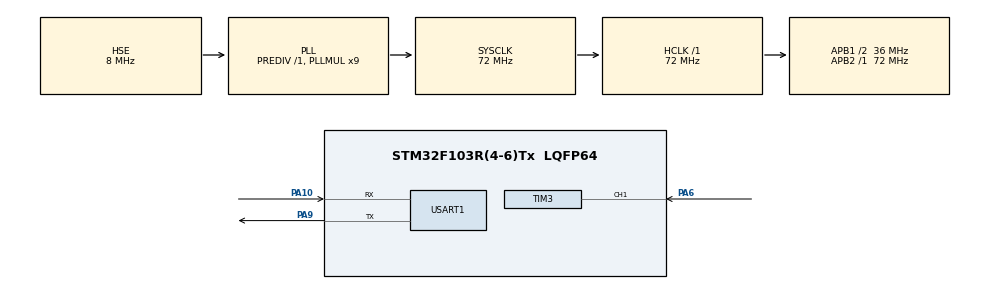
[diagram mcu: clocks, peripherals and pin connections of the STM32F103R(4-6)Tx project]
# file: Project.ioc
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Mcu.Family=STM32F1
Mcu.Name=STM32F103R(4-6)Tx
Mcu.Package=LQFP64
NVIC.PriorityGroup=NVIC_PRIORITYGROUP_4
NVIC.TIM3_IRQn=true\:0\:0\:false\:false\:true\:true\:true
PA10.Mode=Asynchronous
PA10.Signal=USART1_RX
PA6.GPIO_PuPd=GPIO_PULLDOWN
PA6.Signal=S_TIM3_CH1
PA9.Mode=Asynchronous
PA9.Signal=USART1_TX
PD0-OSC_IN.Mode=HSE-External-Oscillator
PD0-OSC_IN.Signal=RCC_OSC_IN
PD1-OSC_OUT.Mode=HSE-External-Oscillator
PD1-OSC_OUT.Signal=RCC_OSC_OUT
ProjectManager.HeapSize=0x200
ProjectManager.StackSize=0x400
ProjectManager.TargetToolchain=MDK-ARM V5
RCC.AHBFreq_Value=72000000
RCC.APB1CLKDivider=RCC_HCLK_DIV2
RCC.APB1Freq_Value=36000000
RCC.APB1TimFreq_Value=72000000
RCC.APB2Freq_Value=72000000
RCC.APB2TimFreq_Value=72000000
RCC.HCLKFreq_Value=72000000
RCC.PLLMUL=RCC_PLL_MUL9
RCC.PLLSourceVirtual=RCC_PLLSOURCE_HSE
RCC.SYSCLKFreq_VALUE=72000000
RCC.SYSCLKSource=RCC_SYSCLKSOURCE_PLLCLK
RCC.USBFreq_Value=72000000
SH.S_TIM3_CH1.0=TIM3_CH1,Input_Capture1_from_TI1
TIM3.AutoReloadPreload=TIM_AUTORELOAD_PRELOAD_ENABLE
TIM3.Channel-Input_Capture1_from_TI1=TIM_CHANNEL_1
TIM3.Period=65535
TIM3.Prescaler=71
USART1.VirtualMode=VM_ASYNC
VP_SYS_VS_ND.Mode=No_Debug
VP_TIM3_VS_ClockSourceINT.Mode=Internal
board=custom

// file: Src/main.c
/**
  ******************************************************************************
  * @file           : main.c
  * @brief          : Main program body
  ******************************************************************************
  ** This notice applies to any and all portions of this file
  * that are not between comment pairs USER CODE BEGIN and
  * USER CODE END. Other portions of this file, whether
  * inserted by the user or by software development tools
  * are owned by their respective copyright owners.
  *
  * COPYRIGHT(c) 2019 STMicroelectronics
  *
  * Redistribution and use in source and binary forms, with or without modification,
  * are permitted provided that the following conditions are met:
  *   1. Redistributions of source code must retain the above copyright notice,
  *      this list of conditions and the following disclaimer.
  *   2. Redistributions in binary form must reproduce the above copyright notice,
  *      this list of conditions and the following disclaimer in the documentation
  *      and/or other materials provided with the distribution.
  *   3. Neither the name of STMicroelectronics nor the names of its contributors
  *      may be used to endorse or promote products derived from this software
  *      without specific prior written permission.
  *
  * THIS SOFTWARE IS PROVIDED BY THE COPYRIGHT HOLDERS AND CONTRIBUTORS "AS IS"
  * AND ANY EXPRESS OR IMPLIED WARRANTIES, INCLUDING, BUT NOT LIMITED TO, THE
  * IMPLIED WARRANTIES OF MERCHANTABILITY AND FITNESS FOR A PARTICULAR PURPOSE ARE
  * DISCLAIMED. IN NO EVENT SHALL THE COPYRIGHT HOLDER OR CONTRIBUTORS BE LIABLE
  * FOR ANY DIRECT, INDIRECT, INCIDENTAL, SPECIAL, EXEMPLARY, OR CONSEQUENTIAL
  * DAMAGES (INCLUDING, BUT NOT LIMITED TO, PROCUREMENT OF SUBSTITUTE GOODS OR
  * SERVICES; LOSS OF USE, DATA, OR PROFITS; OR BUSINESS INTERRUPTION) HOWEVER
  * CAUSED AND ON ANY THEORY OF LIABILITY, WHETHER IN CONTRACT, STRICT LIABILITY,
  * OR TORT (INCLUDING NEGLIGENCE OR OTHERWISE) ARISING IN ANY WAY OUT OF THE USE
  * OF THIS SOFTWARE, EVEN IF ADVISED OF THE POSSIBILITY OF SUCH DAMAGE.
  *
  ******************************************************************************
  */
/*
@file	《嵌入式微控制器原理及设计》书籍（作者:毕盛等 Email:picy@scut.edu.cn  电子工业出版社）配套实例 ch8.3
*/
#include "main.h"
#include "stm32f1xx_hal.h"
#include "tim.h"
#include "usart.h"
#include "gpio.h"
#include "stdio.h"
#include "string.h"

typedef struct              //测量高电平脉宽
{
	uint8_t   ucFinishFlag;
	uint8_t   ucStartFlag;
	uint16_t  usCtr;
	uint16_t  usPeriod;
}STRUCT_CAPTURE;

STRUCT_CAPTURE strCapture = { 0, 0, 0 };

/* USER CODE BEGIN PV */
/* Private variables ---------------------------------------------------------*/
// 定义定时器预分频，定时器实际时钟频率为：72MHz/（GENERAL_TIMx_PRESCALER+1）
#define TIM_PRESCALER               71  // 实际时钟频率为：36kHz

// 定义定时器周期，当定时器开始计数到GENERAL_TIMx_PERIOD值是更新定时器并生成对应事件和中断
#define GENERAL_TIM_PERIOD                  0xFFFF
#define GENERAL_TIM_STRAT_ICPolarity        TIM_INPUTCHANNELPOLARITY_RISING          //测量的起始边沿
#define GENERAL_TIM_END_ICPolarity          TIM_INPUTCHANNELPOLARITY_FALLING         //测量的结束边沿

/* USER CODE END PV */

void SystemClock_Config(void);

/* USER CODE BEGIN PFP */
/* Private function prototypes -----------------------------------------------*/

/* USER CODE END PFP */

/* USER CODE BEGIN 0 */
//重定义fputc函数
int fputc(int ch, FILE *f)
{
	while((USART1->SR&0X40)==0);//循环发送,直到发送完毕
	USART1->DR=(uint8_t)ch;
	return ch;
}
/* USER CODE END 0 */

int main(void)
{
  /* USER CODE BEGIN 1 */
  uint32_t l_TmrClk, L_Time;
  /* USER CODE END 1 */
  uint8_t txbuf[50];
  /* MCU Configuration----------------------------------------------------------*/

  /* Reset of all peripherals, Initializes the Flash interface and the Systick. */
  HAL_Init();

  /* Configure the system clock */
  SystemClock_Config();

  /* Initialize all configured peripherals */
  MX_GPIO_Init();
  MX_TIM3_Init();
  MX_USART1_UART_Init();
  /* USER CODE BEGIN 2 */
  //printf ( "Press the Key0,please!\n" );
  /* USER CODE END 2 */
	l_TmrClk = HAL_RCC_GetHCLKFreq()/TIM_PRESCALER;  //获取定时器时钟周期
  HAL_TIM_Base_Start_IT(&htim3);  //启动定时器

  /* 启动定时器通道输入捕获并开启中断 */
  HAL_TIM_IC_Start_IT(&htim3,TIM_CHANNEL_1);
	memcpy(txbuf,"捕获脉冲宽度实验-----\r\n",100);
  HAL_UART_Transmit(&huart1,txbuf,strlen((char *)txbuf),1000);
  /* Infinite loop */
  while (1)
  {
    if(strCapture.ucFinishFlag == 1 )/* 完成测量高电平脉宽 */
		{
			L_Time = strCapture .usPeriod * GENERAL_TIM_PERIOD + strCapture .usCtr;/* 计算高电平计数值 */
			/* 打印高电平脉宽时间 */
			printf ( "%d.%d s \r\n", L_Time / l_TmrClk, L_Time % l_TmrClk );
			//printf("%d \r\n",L_Time);
			strCapture .ucFinishFlag = 0;
		}
  }
}

/**
  * 函数功能: 非阻塞模式下定时器的回调函数
  * 输入参数: htim：定时器句柄
  * 返 回 值: 无
  * 说    明: 无
  */
void HAL_TIM_PeriodElapsedCallback(TIM_HandleTypeDef *htim)
{
  strCapture .usPeriod ++;
}

/**
  * 函数功能: 定时器输入捕获中断回调函数
  * 输入参数: htim：定时器句柄
  * 返 回 值: 无
  * 说    明: 无
  */
void HAL_TIM_IC_CaptureCallback(TIM_HandleTypeDef *htim)
{
  TIM_IC_InitTypeDef sConfigIC;

  if ( strCapture .ucStartFlag == 0 )
  {
    htim3.Instance->CNT=0; // 清零定时器计数
    strCapture .usPeriod = 0;
    strCapture .usCtr = 0;

    //配置输入捕获参数，主要是修改触发电平
    sConfigIC.ICPolarity = GENERAL_TIM_END_ICPolarity;
    sConfigIC.ICSelection = TIM_ICSELECTION_DIRECTTI;
    sConfigIC.ICPrescaler = TIM_ICPSC_DIV1;
    sConfigIC.ICFilter = 0;
    HAL_TIM_IC_ConfigChannel(&htim3, &sConfigIC, TIM_CHANNEL_1);
    // 清除中断标志位
    __HAL_TIM_CLEAR_IT(htim, TIM_IT_CC1);
    // 启动输入捕获并开启中断
    HAL_TIM_IC_Start_IT(&htim3,TIM_CHANNEL_1);
    strCapture .ucStartFlag = 1;
  }
  else
  {

    // 获取定时器计数值
    strCapture .usCtr = HAL_TIM_ReadCapturedValue(&htim3,TIM_CHANNEL_1);
    // 配置输入捕获参数，主要是修改触发电平
    sConfigIC.ICPolarity = GENERAL_TIM_STRAT_ICPolarity;
    sConfigIC.ICSelection = TIM_ICSELECTION_DIRECTTI;
    sConfigIC.ICPrescaler = TIM_ICPSC_DIV1;
    sConfigIC.ICFilter = 0;
    HAL_TIM_IC_ConfigChannel(&htim3, &sConfigIC, TIM_CHANNEL_1);

    // 清除中断标志位
    __HAL_TIM_CLEAR_IT(htim, TIM_IT_CC1);
    // 启动输入捕获并开启中断
    HAL_TIM_IC_Start_IT(&htim3,TIM_CHANNEL_1);
    strCapture .ucStartFlag = 0;
    strCapture .ucFinishFlag = 1;
  }
}

void SystemClock_Config(void)
{

  RCC_OscInitTypeDef RCC_OscInitStruct;
  RCC_ClkInitTypeDef RCC_ClkInitStruct;

    /**Initializes the CPU, AHB and APB busses clocks
    */
  RCC_OscInitStruct.OscillatorType = RCC_OSCILLATORTYPE_HSE;
  RCC_OscInitStruct.HSEState = RCC_HSE_ON;
  RCC_OscInitStruct.HSEPredivValue = RCC_HSE_PREDIV_DIV1;
  RCC_OscInitStruct.HSIState = RCC_HSI_ON;
  RCC_OscInitStruct.PLL.PLLState = RCC_PLL_ON;
  RCC_OscInitStruct.PLL.PLLSource = RCC_PLLSOURCE_HSE;
  RCC_OscInitStruct.PLL.PLLMUL = RCC_PLL_MUL9;
  if (HAL_RCC_OscConfig(&RCC_OscInitStruct) != HAL_OK)
  {
    _Error_Handler(__FILE__, __LINE__);
  }

    /**Initializes the CPU, AHB and APB busses clocks
    */
  RCC_ClkInitStruct.ClockType = RCC_CLOCKTYPE_HCLK|RCC_CLOCKTYPE_SYSCLK
                              |RCC_CLOCKTYPE_PCLK1|RCC_CLOCKTYPE_PCLK2;
  RCC_ClkInitStruct.SYSCLKSource = RCC_SYSCLKSOURCE_PLLCLK;
  RCC_ClkInitStruct.AHBCLKDivider = RCC_SYSCLK_DIV1;
  RCC_ClkInitStruct.APB1CLKDivider = RCC_HCLK_DIV2;
  RCC_ClkInitStruct.APB2CLKDivider = RCC_HCLK_DIV1;

  if (HAL_RCC_ClockConfig(&RCC_ClkInitStruct, FLASH_LATENCY_2) != HAL_OK)
  {
    _Error_Handler(__FILE__, __LINE__);
  }

    /**Configure the Systick interrupt time
    */
  HAL_SYSTICK_Config(HAL_RCC_GetHCLKFreq()/1000);

    /**Configure the Systick
    */
  HAL_SYSTICK_CLKSourceConfig(SYSTICK_CLKSOURCE_HCLK);

  /* SysTick_IRQn interrupt configuration */
  HAL_NVIC_SetPriority(SysTick_IRQn, 0, 0);
}

void _Error_Handler(char *file, int line)
{
  while(1)
  {
  }
}

/************************ (C) COPYRIGHT STMicroelectronics *****END OF FILE****/
